# DMASS_DTHE_DMASS_DTHE_DTHE_DTHE_CFG_PKEV4_WRAP_VBUSP_PKEV4_40810000h register map
Vendor: Texas Instruments
Peripheral module from a debugger description file (folder am62L).
Registers are 32-bit, read-only, reset 0x0 unless marked. A register's access mark holds for its fields unless they carry their own. Offsets are as the file gives them; lines under a group give offsets from that group; [hi:lo] are bit positions; {n}, {i} and the like mark numbered series; 'fields as' and 'values as' point back to an identical list; <NAME> marks a mode.

## DMASS_DTHE_DTHE_DTHE_CFG_PKEV4_WRAP_VBUSP_PKEV4
0x00 DMASS_DTHE_DTHE_DTHE_CFG_PKEV4_WRAP_VBUSP_PKEV4_PKE_RESET_CTRL rw — Reset control for Command FIFO and flush control for MAU Core. This register is not self-clearing.
  [20] PKEFLUSH — pkeFlush input to PKE(active high). When set, this bit will assert the mauFlush input to MAU Core, resets command FIFO, issues reset to MCG. Flush sequence will complete some cycles after this bit is cleared. PKE will remain in flush state as long as this bit is asserted.
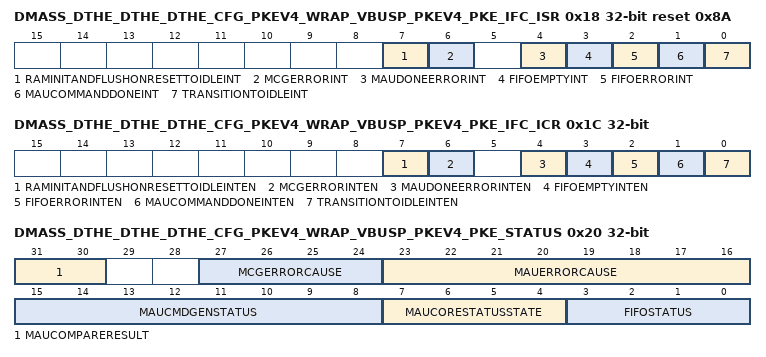
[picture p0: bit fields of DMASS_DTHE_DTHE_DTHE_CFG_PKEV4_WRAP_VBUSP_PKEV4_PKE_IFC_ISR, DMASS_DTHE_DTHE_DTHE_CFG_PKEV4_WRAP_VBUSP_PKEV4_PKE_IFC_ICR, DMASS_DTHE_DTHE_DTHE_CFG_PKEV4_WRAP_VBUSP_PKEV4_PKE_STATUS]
0x18 DMASS_DTHE_DTHE_DTHE_CFG_PKEV4_WRAP_VBUSP_PKEV4_PKE_IFC_ISR rw reset 0x8A — Interrupt Status Register. Writing a 1 to any bit in this register clears the associated interrupt. Cleared on pkeFlush.
  [7] RAMINITANDFLUSHONRESETTOIDLEINT — Asserted when SRAM initialization (when enabled) or FLUSH sequence after reset are completed. The PKE core will go into IDLE state when SRAM initialization (when enabled) and FLUSH sequence after resset finish.
  [6] MCGERRORINT — Asserted when MCG status indicates ERROR/PANIC. This interrupt is re-asserted when cleared if MCG status is MCG_ERROR/PANIC in PKE_STATUS register
  [4] MAUDONEERRORINT — This interrupt is re-asserted when cleared if MAU Core Status is ERROR/PANIC in PKE_STATUS register.
  [3] FIFOEMPTYINT — This interrupt is asserted when FIFO transitions to empty.
  [2] FIFOERRORINT — This interrupt is re-asserted when cleared if FIFO Write Error is asserted in PKE_STATUS register.
  [1] MAUCOMMANDDONEINT — This interrupt is asserted when MAU status transition from BUSY to READY/ERROR/PANIC.
  [0] TRANSITIONTOIDLEINT — Transition to idle
0x1C DMASS_DTHE_DTHE_DTHE_CFG_PKEV4_WRAP_VBUSP_PKEV4_PKE_IFC_ICR rw — Interrupt Control Register. Writing a 1 to any bit in this register enables the associated interrupt.
  [7] RAMINITANDFLUSHONRESETTOIDLEINTEN — See PKE_IFC_ISR register
  [6] MCGERRORINTEN — See PKE_IFC_ISR register
  [4] MAUDONEERRORINTEN — See PKE_IFC_ISR register
  [3] FIFOEMPTYINTEN — See PKE_IFC_ISR register
  [2] FIFOERRORINTEN — See PKE_IFC_ISR register
  [1] MAUCOMMANDDONEINTEN — See PKE_IFC_ISR register
  [0] TRANSITIONTOIDLEINTEN — See PKE_IFC_ISR register
0x20 DMASS_DTHE_DTHE_DTHE_CFG_PKEV4_WRAP_VBUSP_PKEV4_PKE_STATUS — Reports the status of the Command FIFO, Mau Core, and Mau Command Generator.
  [31:30] MAUCOMPARERESULT — Reflects the status of compare result when compare command is completed by MAU core only when the MAU command is issued by AHB. Will be cleared on pkeFlush.
  [27:24] MCGERRORCAUSE — Optional field. MCG currently does not advertise error cause. Will be cleared on pkeFlush.
  [23:16] MAUERRORCAUSE — Optional field. Refer to the MAU section for more details. Will be cleared on pkeFlush
  [15:8] MAUCMDGENSTATUS — This reflects the command generator unit status. Cleared when MCG Status is error and pkeFlush is issued. 0x0: MCG_IDLE. 0x1: MCG_BUSY. 0x4: MCG_ERROR. 0x8: MCG_PANIC.
  [7:4] MAUCORESTATUSSTATE — 0x0 : MAU_READY. 0x1: MAU_BUSY. 0x2: MAU_ERROR. 0x8: MAU_PANIC.
  [3:0] FIFOSTATUS — This reflects the command FIFO status. Cleared on pkeFlush.
0x30 DMASS_DTHE_DTHE_DTHE_CFG_PKEV4_WRAP_VBUSP_PKEV4_PKE_SCRATCH rw reset 0x76543210 — Scratch register for testing connectivity
  [31:0] MAUIFCSCRATCH — On reset, this value is 0x7654_3210
0x34 DMASS_DTHE_DTHE_DTHE_CFG_PKEV4_WRAP_VBUSP_PKEV4_MAU_MIN_LEN reset 0x3 — Specifies the minimum length of commands
  [31:0] MAUMINLEN — This constant register always gives the value of the constant MAU_MIN_LEN.
0x38 DMASS_DTHE_DTHE_DTHE_CFG_PKEV4_WRAP_VBUSP_PKEV4_MAU_MAX_LEN reset 0x40 — Specifies the maximum length of commands
  [31:0] MAUMAXLEN — This constant register always gives the value of the constant MAU_MAX_LEN.
0x3C DMASS_DTHE_DTHE_DTHE_CFG_PKEV4_WRAP_VBUSP_PKEV4_PKE_VERSION reset 0x4 — Specifies the PKE version
  [31:0] PKEVERSION — This constant register always gives the version of PKE.
0x40 DMASS_DTHE_DTHE_DTHE_CFG_PKEV4_WRAP_VBUSP_PKEV4_MCG_COMMANDS_ENABLED_0 reset 0xFC5FFFFF — Specifies the MCG commands enabled
  [31:0] MCGCOMMANDSENABLED — This constant register gives the MCG commands enabled in the current version
0x44 DMASS_DTHE_DTHE_DTHE_CFG_PKEV4_WRAP_VBUSP_PKEV4_MCG_COMMANDS_ENABLED_1 reset 0x3E — Specifies the MCG commands enabled
  fields as DMASS_DTHE_DTHE_DTHE_CFG_PKEV4_WRAP_VBUSP_PKEV4_MCG_COMMANDS_ENABLED_0
0x48 DMASS_DTHE_DTHE_DTHE_CFG_PKEV4_WRAP_VBUSP_PKEV4_MCG_COMMANDS_ENABLED_2 — Specifies the MCG commands enabled
  fields as DMASS_DTHE_DTHE_DTHE_CFG_PKEV4_WRAP_VBUSP_PKEV4_MCG_COMMANDS_ENABLED_0
0x4C DMASS_DTHE_DTHE_DTHE_CFG_PKEV4_WRAP_VBUSP_PKEV4_MCG_COMMANDS_ENABLED_3 — Specifies the MCG commands enabled
  fields as DMASS_DTHE_DTHE_DTHE_CFG_PKEV4_WRAP_VBUSP_PKEV4_MCG_COMMANDS_ENABLED_0
{0x50+4i} DMASS_DTHE_DTHE_DTHE_CFG_PKEV4_WRAP_VBUSP_PKEV4_PKE_PRNG_SEED_{i} wo (i=0..3) — Register to reseed the PRNG
  [31:0] PKEPRNGSEED_{i} — When written all 128 bits in this register will reseed PRNG inside PKE. The reseed happens when register at 0x5C is written. So, it is important to write 0x50, 0x54, 0x58 before Writing 0x5C. Reseed completes in one cycle, so no status is returned.
0x60 DMASS_DTHE_DTHE_DTHE_CFG_PKEV4_WRAP_VBUSP_PKEV4_PKE_WORD_SIZE reset 0x40 — Specifies the datapath configuration for this PKE IP
  [31:0] PKEWORDSIZE — Constant register
0x64 DMASS_DTHE_DTHE_DTHE_CFG_PKEV4_WRAP_VBUSP_PKEV4_PKE_CURVES_IN_ROM_0 reset 0x1FE00BE — Specifies supported curves in ROM
  [31:0] PKECURVESINROM — Please see spec for detail
0x68 DMASS_DTHE_DTHE_DTHE_CFG_PKEV4_WRAP_VBUSP_PKEV4_PKE_CURVES_IN_ROM_1 reset 0x6 — Specifies supported curves in ROM
  [31:0] PKECURVESINROM — Please see spec for detail
0x6C DMASS_DTHE_DTHE_DTHE_CFG_PKEV4_WRAP_VBUSP_PKEV4_PKE_SPECIAL_PRIMES reset 0xFF — Specifies the curves with special primes which have special prime unit implemented
  [31:0] PKESPECIALPRIMES — please see spec
0x70 DMASS_DTHE_DTHE_DTHE_CFG_PKEV4_WRAP_VBUSP_PKEV4_PKE_SRAM_ADDR_MIN — Specifies the minimum SRAM address
  [31:0] PKESRAMADDRMIN — constant value of mauWcMemMinAddrConst
0x74 DMASS_DTHE_DTHE_DTHE_CFG_PKEV4_WRAP_VBUSP_PKEV4_PKE_SRAM_ADDR_MAX reset 0x1FF — Specifies the maximum SRAM address
  [31:0] PKESRAMADDRMAX — constant value of mauWcMemMaxAddrConst
0x80 DMASS_DTHE_DTHE_DTHE_CFG_PKEV4_WRAP_VBUSP_PKEV4_MAU_COMMAND wo — MAU command word. Writing to this address queues an update to the mauCommandIn register.
  [31:0] MAUCOMMAND — contains mauCommandIn[31:0]
0x88 DMASS_DTHE_DTHE_DTHE_CFG_PKEV4_WRAP_VBUSP_PKEV4_MAU_MCG_COMMAND wo — Writes to this address will start a new operation in MCG. Writes are queued in Command Register Queue and will complete only when generator is ready to accept a new command.
  [31:0] MAUCOMMANDCMDGEN — MauCmdGen command
0x2000 DMASS_DTHE_DTHE_DTHE_CFG_PKEV4_WRAP_VBUSP_PKEV4_CONTEXT_MEM_j rw — Each word-aligned address accesses a word in the Working Context Memory.
  [31:0] CONTEXT_WORD — context data
